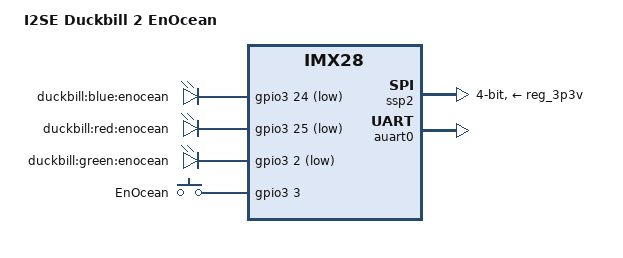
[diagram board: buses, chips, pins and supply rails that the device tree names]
/*
 * Copyright (C) 2015-2016 I2SE GmbH <info@i2se.com>
 *
 * The code contained herein is licensed under the GNU General Public
 * License. You may obtain a copy of the GNU General Public License
 * Version 2 or later at the following locations:
 *
 * http://www.opensource.org/licenses/gpl-license.html
 * http://www.gnu.org/copyleft/gpl.html
 */

/dts-v1/;
#include <dt-bindings/input/input.h>
#include "imx28-duckbill-2-common.dtsi"

/ {
	model = "I2SE Duckbill 2 EnOcean";
	compatible = "i2se,duckbill", "fsl,imx28";

	apb@80000000 {
		apbh@80000000 {
			ssp2: ssp@80014000 {
				compatible = "fsl,imx28-mmc";
				pinctrl-names = "default";
				pinctrl-0 = <&mmc2_4bit_pins_b
					&mmc2_cd_cfg &mmc2_sck_cfg_b>;
				bus-width = <4>;
				vmmc-supply = <&reg_3p3v>;
				status = "okay";
			};

			pinctrl@80018000 {
				enocean_led_pins: enocean_led_pins@0 {
					reg = <0>;
					fsl,pinmux-ids = <
						MX28_PAD_AUART0_CTS__GPIO_3_2
						MX28_PAD_I2C0_SCL__GPIO_3_24
						MX28_PAD_I2C0_SDA__GPIO_3_25
					>;
					fsl,drive-strength = <MXS_DRIVE_4mA>;
					fsl,voltage = <MXS_VOLTAGE_HIGH>;
					fsl,pull-up = <MXS_PULL_DISABLE>;
				};

				enocean_button: enocean_button@0 {
					reg = <0>;
					fsl,pinmux-ids = <
						MX28_PAD_AUART0_RTS__GPIO_3_3
					>;
					fsl,drive-strength = <MXS_DRIVE_4mA>;
					fsl,voltage = <MXS_VOLTAGE_HIGH>;
					fsl,pull-up = <MXS_PULL_DISABLE>;
				};
			};
		};

		apbx@80040000 {
			auart0: serial@8006a000 {
				pinctrl-names = "default";
				pinctrl-0 = <&auart0_2pins_a>;
				status = "okay";
			};
		};
	};

	enocean_leds {
		compatible = "gpio-leds";
		pinctrl-names = "default";
		pinctrl-0 = <&enocean_led_pins>;

		enocean_blue {
			label = "duckbill:blue:enocean";
			gpios = <&gpio3 24 GPIO_ACTIVE_LOW>;
		};

		enocean_red {
			label = "duckbill:red:enocean";
			gpios = <&gpio3 25 GPIO_ACTIVE_LOW>;
		};

		enocean_green {
			label = "duckbill:green:enocean";
			gpios = <&gpio3 2 GPIO_ACTIVE_LOW>;
		};
	};

	gpio_keys {
		compatible = "gpio-keys";
		#address-cells = <1>;
		#size-cells = <0>;
		pinctrl-names = "default";
		pinctrl-0 = <&enocean_button>;

		enocean {
			label = "EnOcean";
			linux,code = <KEY_NEW>;
			gpios = <&gpio3 3 GPIO_ACTIVE_HIGH>;
		};
	};
};
